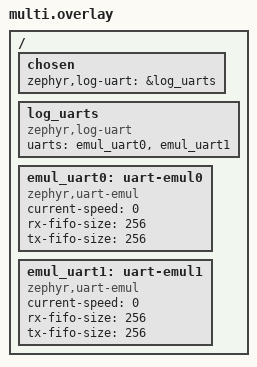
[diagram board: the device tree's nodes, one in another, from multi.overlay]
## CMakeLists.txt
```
# Copyright (c) 2023 Meta
# SPDX-License-Identifier: Apache-2.0

cmake_minimum_required(VERSION 3.20.0)
find_package(Zephyr REQUIRED HINTS $ENV{ZEPHYR_BASE})
project(log_backend_uart_test)

FILE(GLOB app_sources src/*.c)
target_sources(app PRIVATE ${app_sources})
```

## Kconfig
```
# Copyright (c) 2021 Nordic Semiconductor ASA
# SPDX-License-Identifier: Apache-2.0

module = SAMPLE_MODULE
module-str = Test logging API
source "subsys/logging/Kconfig.template.log_config"

source "Kconfig.zephyr"
```

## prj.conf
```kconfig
# Copyright (c) 2023 Meta
# SPDX-License-Identifier: Apache-2.0

CONFIG_ZTEST=y
CONFIG_ASSERT=y
CONFIG_TEST_LOGGING_DEFAULTS=n
CONFIG_SERIAL=y
CONFIG_EMUL=y

CONFIG_LOG=y
CONFIG_LOG_BACKEND_UART=y
CONFIG_LOG_MODE_IMMEDIATE=y
CONFIG_LOG_PRINTK=n
#
# Disable all potential other default backends
CONFIG_LOG_BACKEND_NATIVE_POSIX=n
CONFIG_LOG_BACKEND_RTT=n
CONFIG_LOG_BACKEND_XTENSA_SIM=n
```

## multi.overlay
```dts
/*
 * Copyright (c) 2023 Meta
 *
 * SPDX-License-Identifier: Apache-2.0
 */

/ {
	chosen {
		zephyr,log-uart = &log_uarts;
	};

	log_uarts: log_uarts {
		compatible = "zephyr,log-uart";
		uarts = <&emul_uart0 &emul_uart1>;
	};

	emul_uart0: uart-emul0 {
		compatible = "zephyr,uart-emul";
		status = "okay";
		current-speed = <0>;
		rx-fifo-size = <256>;
		tx-fifo-size = <256>;
	};

	emul_uart1: uart-emul1 {
		compatible = "zephyr,uart-emul";
		status = "okay";
		current-speed = <0>;
		rx-fifo-size = <256>;
		tx-fifo-size = <256>;
	};
};
```

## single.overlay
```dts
/*
 * Copyright (c) 2023 Meta
 *
 * SPDX-License-Identifier: Apache-2.0
 */

/ {
	chosen {
		zephyr,log-uart = &log_uarts;
	};

	log_uarts: log_uarts {
		compatible = "zephyr,log-uart";
		uarts = <&emul_uart0>;
	};

	emul_uart0: uart-emul0 {
		compatible = "zephyr,uart-emul";
		current-speed = <0>;
		rx-fifo-size = <256>;
		tx-fifo-size = <256>;
		status = "okay";
	};
};
```

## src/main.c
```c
/*
 * Copyright (c) 2023 Meta
 *
 * SPDX-License-Identifier: Apache-2.0
 */

#include <zephyr/ztest.h>
#include <zephyr/logging/log.h>
#include <zephyr/logging/log_backend.h>
#include <zephyr/drivers/uart.h>
#include <zephyr/drivers/serial/uart_emul.h>

LOG_MODULE_REGISTER(test, CONFIG_SAMPLE_MODULE_LOG_LEVEL);

#define EMUL_UART_NUM             DT_NUM_INST_STATUS_OKAY(zephyr_uart_emul)
#define EMUL_UART_NODE(i)         DT_NODELABEL(emul_uart##i)
#define EMUL_UART_DEV_INIT(i, _)  DEVICE_DT_GET(EMUL_UART_NODE(i))
#define EMUL_UART_TX_FIFO_SIZE(i) DT_PROP(EMUL_UART_NODE(i), tx_fifo_size)
#define SAMPLE_DATA_SIZE          EMUL_UART_TX_FIFO_SIZE(0)

#define TEST_DATA "0123456789ABCDEF"
/* Assert that size of the test string (without '\0') fits in the SAMPLE_DATA_SIZE */
BUILD_ASSERT((sizeof(TEST_DATA) - 1) < SAMPLE_DATA_SIZE);

struct log_backend_uart_fixture {
	const struct device *dev[EMUL_UART_NUM];
};

static void *uart_emul_setup(void)
{
	static struct log_backend_uart_fixture fixture = {
		.dev = {LISTIFY(EMUL_UART_NUM, EMUL_UART_DEV_INIT, (,))}};

	for (size_t i = 0; i < EMUL_UART_NUM; i++) {
		zassert_not_null(fixture.dev[i]);
	}

	return &fixture;
}

static void uart_emul_before(void *f)
{
	struct log_backend_uart_fixture *fixture = f;

	for (size_t i = 0; i < EMUL_UART_NUM; i++) {
		uart_irq_tx_disable(fixture->dev[i]);
		uart_irq_rx_disable(fixture->dev[i]);

		uart_emul_flush_rx_data(fixture->dev[i]);
		uart_emul_flush_tx_data(fixture->dev[i]);

		uart_err_check(fixture->dev[i]);
	}
}

/**
 * @brief Verify the UART log backend delivers output to every instance.
 *
 * @details
 * Validate that the UART logging backend can be instantiated multiple times and
 * that a single raw log record is delivered to the UART of every backend
 * instance. Emulated UARTs are used to capture and compare the transmitted
 * bytes, confirming logging to multiple UART backends/system resources.
 *
 * Test steps:
 * - Confirm the number of registered backends matches the number of emulated
 *   UARTs.
 * - Emit one raw log record.
 * - Read the TX data of each emulated UART and compare against the expected
 *   string.
 *
 * Expected result:
 * - Every UART backend instance transmits exactly the logged string.
 *
 * @see LOG_RAW()
 * @ingroup logging_tests
 * @verifies ZEP-SRS-11-5
 */
ZTEST_F(log_backend_uart, test_log_backend_uart_multi_instance)
{
	/* Prevent stack overflow by making it static */
	static uint8_t tx_content[SAMPLE_DATA_SIZE];
	size_t tx_len;

	zassert_equal(log_backend_count_get(), EMUL_UART_NUM, "Unexpected number of instance(s)");

	LOG_RAW(TEST_DATA);

	for (size_t i = 0; i < EMUL_UART_NUM; i++) {
		memset(tx_content, 0, sizeof(tx_content));

		tx_len = uart_emul_get_tx_data(fixture->dev[i], tx_content, sizeof(tx_content));
		zassert_equal(tx_len, strlen(TEST_DATA),
			      "%zu: TX buffer length does not match. Expected %zu, got %zu",
			      i, strlen(TEST_DATA), tx_len);
		zassert_mem_equal(tx_content, TEST_DATA, strlen(TEST_DATA));
	}
}

ZTEST_SUITE(log_backend_uart, NULL, uart_emul_setup, uart_emul_before, NULL, NULL);
```
